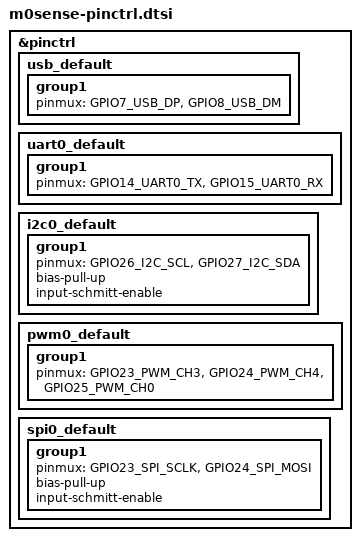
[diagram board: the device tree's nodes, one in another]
/*
 * SPDX-FileCopyrightText: Copyright The Zephyr Project Contributors
 * SPDX-License-Identifier: Apache-2.0
 */

&pinctrl {
	usb_default: usb_default {
		group1 {
			pinmux = <GPIO7_USB_DP>,
				 <GPIO8_USB_DM>;
		};
	};

	uart0_default: uart0_default {
		group1 {
			pinmux = <GPIO14_UART0_TX>,
				 <GPIO15_UART0_RX>;
		};
	};

	i2c0_default: i2c0_default {
		group1 {
			pinmux = <GPIO26_I2C_SCL>,
				 <GPIO27_I2C_SDA>;
			bias-pull-up;
			input-schmitt-enable;
		};
	};

	pwm0_default: pwm0_default {
		group1 {
			pinmux = <GPIO23_PWM_CH3>,
				 <GPIO24_PWM_CH4>,
				 <GPIO25_PWM_CH0>;
		};
	};

	spi0_default: spi0_default {
		group1 {
			pinmux = <GPIO23_SPI_SCLK>,
				 <GPIO24_SPI_MOSI>;
			bias-pull-up;
			input-schmitt-enable;
		};
	};
};
